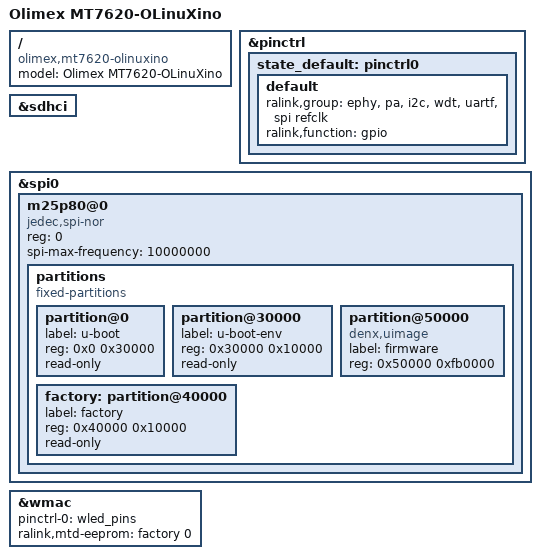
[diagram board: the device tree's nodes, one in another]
/dts-v1/;

#include "mt7620a.dtsi"

#include <dt-bindings/gpio/gpio.h>
#include <dt-bindings/input/input.h>

/ {
	compatible = "olimex,mt7620-olinuxino", "ralink,mt7620a-soc";
	model = "Olimex MT7620-OLinuXino";
};

&pinctrl {
	state_default: pinctrl0 {
		default {
			ralink,group = "ephy", "pa", "i2c", "wdt", "uartf", "spi refclk";
			ralink,function = "gpio";
		};
	};
};

&sdhci {
	status = "okay";
};

&spi0 {
	status = "okay";

	m25p80@0 {
		compatible = "jedec,spi-nor";
		reg = <0>;
		spi-max-frequency = <10000000>;

		partitions {
			compatible = "fixed-partitions";
			#address-cells = <1>;
			#size-cells = <1>;

			partition@0 {
				label = "u-boot";
				reg = <0x0 0x30000>;
				read-only;
			};

			partition@30000 {
				label = "u-boot-env";
				reg = <0x30000 0x10000>;
				read-only;
			};

			factory: partition@40000 {
				label = "factory";
				reg = <0x40000 0x10000>;
				read-only;
			};

			partition@50000 {
				compatible = "denx,uimage";
				label = "firmware";
				reg = <0x50000 0xfb0000>;
			};
		};
	};
};


&wmac {
	pinctrl-names = "default";
	pinctrl-0 = <&wled_pins>;
	ralink,mtd-eeprom = <&factory 0>;
};
